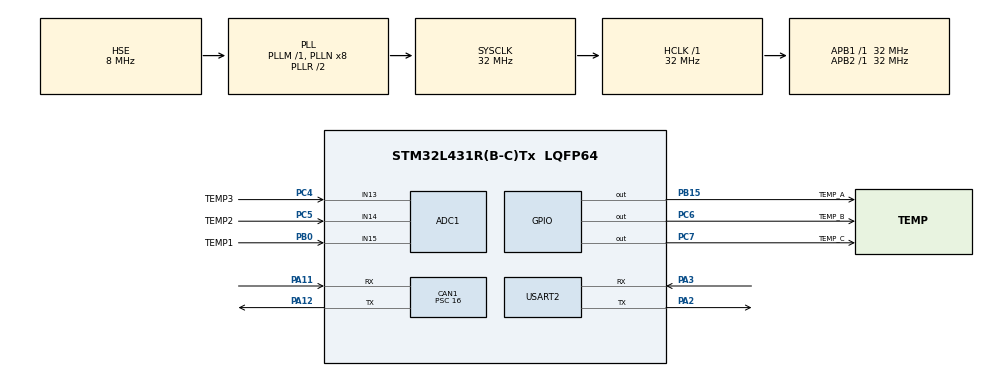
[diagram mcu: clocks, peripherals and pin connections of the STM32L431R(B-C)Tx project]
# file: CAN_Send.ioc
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ADC1.Channel-0\#ChannelRegularConversion=ADC_CHANNEL_15
ADC1.Channel-1\#ChannelRegularConversion=ADC_CHANNEL_14
ADC1.Channel-2\#ChannelRegularConversion=ADC_CHANNEL_13
ADC1.ContinuousConvMode=ENABLE
ADC1.DMAContinuousRequests=ENABLE
ADC1.NbrOfConversion=3
ADC1.NbrOfConversionFlag=1
ADC1.OffsetNumber-0\#ChannelRegularConversion=ADC_OFFSET_NONE
ADC1.OffsetNumber-1\#ChannelRegularConversion=ADC_OFFSET_NONE
ADC1.OffsetNumber-2\#ChannelRegularConversion=ADC_OFFSET_NONE
ADC1.Rank-0\#ChannelRegularConversion=1
ADC1.Rank-1\#ChannelRegularConversion=2
ADC1.Rank-2\#ChannelRegularConversion=3
ADC1.SamplingTime-0\#ChannelRegularConversion=ADC_SAMPLETIME_92CYCLES_5
ADC1.SamplingTime-1\#ChannelRegularConversion=ADC_SAMPLETIME_92CYCLES_5
ADC1.SamplingTime-2\#ChannelRegularConversion=ADC_SAMPLETIME_92CYCLES_5
ADC1.master=1
CAN1.ABOM=DISABLE
CAN1.AWUM=DISABLE
CAN1.BS1=CAN_BS1_5TQ
CAN1.BS2=CAN_BS2_2TQ
CAN1.CalculateBaudRate=250000
CAN1.CalculateTimeBit=4000
CAN1.CalculateTimeQuantum=500.0
CAN1.NART=DISABLE
CAN1.Prescaler=16
CAN1.RFLM=ENABLE
CAN1.TXFP=ENABLE
Dma.ADC1.0.Direction=DMA_PERIPH_TO_MEMORY
Dma.ADC1.0.Instance=DMA1_Channel1
Dma.ADC1.0.MemDataAlignment=DMA_MDATAALIGN_HALFWORD
Dma.ADC1.0.MemInc=DMA_MINC_ENABLE
Dma.ADC1.0.Mode=DMA_CIRCULAR
Dma.ADC1.0.PeriphDataAlignment=DMA_PDATAALIGN_HALFWORD
Dma.ADC1.0.PeriphInc=DMA_PINC_DISABLE
Dma.ADC1.0.Priority=DMA_PRIORITY_MEDIUM
Dma.Request0=ADC1
Mcu.Family=STM32L4
Mcu.Name=STM32L431R(B-C)Tx
Mcu.Package=LQFP64
NVIC.ADC1_IRQn=true\:0\:0\:false\:false\:true\:true\:true\:true
NVIC.CAN1_RX0_IRQn=true\:0\:0\:false\:false\:true\:true\:true\:true
NVIC.CAN1_RX1_IRQn=true\:0\:0\:false\:false\:true\:true\:true\:true
NVIC.CAN1_SCE_IRQn=true\:0\:0\:false\:false\:true\:true\:true\:true
NVIC.CAN1_TX_IRQn=true\:0\:0\:false\:false\:true\:true\:true\:true
NVIC.DMA1_Channel1_IRQn=true\:0\:0\:false\:false\:true\:false\:true\:true
NVIC.PriorityGroup=NVIC_PRIORITYGROUP_4
NVIC.USART2_IRQn=true\:0\:0\:false\:false\:true\:true\:true\:true
PA11.GPIO_Mode=GPIO_MODE_AF_PP
PA11.Mode=CAN_Activate
PA11.Signal=CAN1_RX
PA12.Mode=CAN_Activate
PA12.Signal=CAN1_TX
PA13\ (JTMS-SWDIO).Mode=Serial_Wire
PA13\ (JTMS-SWDIO).Signal=SYS_JTMS-SWDIO
PA14\ (JTCK-SWCLK).Mode=Serial_Wire
PA14\ (JTCK-SWCLK).Signal=SYS_JTCK-SWCLK
PA2.Mode=Asynchronous
PA2.Signal=USART2_TX
PA3.Mode=Asynchronous
PA3.Signal=USART2_RX
PB0.GPIO_Label=TEMP1
PB0.Signal=ADCx_IN15
PB15.GPIO_Label=TEMP_A
PB15.Signal=GPIO_Output
PC14-OSC32_IN\ (PC14).Mode=LSE-External-Oscillator
PC14-OSC32_IN\ (PC14).Signal=RCC_OSC32_IN
PC15-OSC32_OUT\ (PC15).Mode=LSE-External-Oscillator
PC15-OSC32_OUT\ (PC15).Signal=RCC_OSC32_OUT
PC4.GPIO_Label=TEMP3
PC4.Signal=ADCx_IN13
PC5.GPIO_Label=TEMP2
PC5.Signal=ADCx_IN14
PC6.GPIO_Label=TEMP_B
PC6.Signal=GPIO_Output
PC7.GPIO_Label=TEMP_C
PC7.Signal=GPIO_Output
PH0-OSC_IN\ (PH0).Mode=HSE-External-Oscillator
PH0-OSC_IN\ (PH0).Signal=RCC_OSC_IN
PH1-OSC_OUT\ (PH1).Mode=HSE-External-Oscillator
PH1-OSC_OUT\ (PH1).Signal=RCC_OSC_OUT
ProjectManager.HeapSize=0x200
ProjectManager.StackSize=0x400
ProjectManager.TargetToolchain=MDK-ARM V5.27
RCC.ADCFreq_Value=32000000
RCC.AHBFreq_Value=32000000
RCC.APB1Freq_Value=32000000
RCC.APB1TimFreq_Value=32000000
RCC.APB2Freq_Value=32000000
RCC.APB2TimFreq_Value=32000000
RCC.CortexFreq_Value=32000000
RCC.HCLKFreq_Value=32000000
RCC.HSE_VALUE=8000000
RCC.HSI48_VALUE=48000000
RCC.HSI_VALUE=16000000
RCC.MSI_VALUE=4000000
RCC.PLLSourceVirtual=RCC_PLLSOURCE_HSE
RCC.SYSCLKFreq_VALUE=32000000
RCC.SYSCLKSource=RCC_SYSCLKSOURCE_PLLCLK
RCC.VCOOutputFreq_Value=64000000
SH.ADCx_IN13.0=ADC1_IN13,IN13-Single-Ended
SH.ADCx_IN14.0=ADC1_IN14,IN14-Single-Ended
SH.ADCx_IN15.0=ADC1_IN15,IN15-Single-Ended
USART2.VirtualMode-Asynchronous=VM_ASYNC
board=custom

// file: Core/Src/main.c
/* USER CODE BEGIN Header */
/**
  ******************************************************************************
  * @file           : main.c
  * @brief          : Main program body
  ******************************************************************************
  * @attention
  *
  * Copyright (c) 2023 STMicroelectronics.
  * All rights reserved.
  *
  * This software is licensed under terms that can be found in the LICENSE file
  * in the root directory of this software component.
  * If no LICENSE file comes with this software, it is provided AS-IS.
  *
  ******************************************************************************
  */
/* USER CODE END Header */
#include "main.h"
#include "adc.h"
#include "can.h"
#include "dma.h"
#include "usart.h"
#include "gpio.h"

/* USER CODE BEGIN Includes */
uint8_t CAN1_Rx_data[8];
uint8_t CAN1_Tx_data[8];
uint16_t ADC_ConvertedValue[Temp_Sample_Num] = {0};

uint8_t rxbuff[256] = {0};
/* USER CODE END Includes */

void SystemClock_Config(void);

int main(void)
{

  /* MCU Configuration--------------------------------------------------------*/

  /* Reset of all peripherals, Initializes the Flash interface and the Systick. */
  HAL_Init();

  /* Configure the system clock */
  SystemClock_Config();

  /* Initialize all configured peripherals */
  MX_GPIO_Init();
  MX_DMA_Init();
  MX_CAN1_Init();
  MX_USART2_UART_Init();
  MX_ADC1_Init();
  /* USER CODE BEGIN 2 */
	Can_ConfigInit();

	printf("开始测试。\r\n");
  /* USER CODE END 2 */

  /* Infinite loop */
  while (1)
  {

    /* USER CODE BEGIN 3 */

//	CAN_Send();
	HAL_Delay(2000);

//	ADC_DMA_Temper_Sample();
	HAL_Delay(5000);

	HAL_Delay(4000);
			HAL_Delay(4000);
		HAL_Delay(4000);
		GetTemperature();
		HAL_Delay(1000);
//		Display_Temper();

//		ADC_Value_Test();

//
//	CAN_Send_ADCvalue();
//	HAL_Delay(5000);

//	ADC_Vol_Temper_Conver();
//	HAL_Delay(100);

//	CAN_ReceData();
//	HAL_CAN_RxFifo0MsgPendingCallback(&hcan1);
//		printf("receive = \r\n");
//	for(int i=0;i<8;i++)
//		{
//			printf("0x%x ,",CAN1_Rx_data[i]);
//		}
//
//		printf("\r\nRxMessage.StdId = 0x%x \n",RxMessage.StdId);
//		printf("RxMessage.ExtId = 0x%x \n",RxMessage.ExtId);
  }
  /* USER CODE END 3 */
}

void SystemClock_Config(void)
{
  RCC_OscInitTypeDef RCC_OscInitStruct = {0};
  RCC_ClkInitTypeDef RCC_ClkInitStruct = {0};

  /** Configure the main internal regulator output voltage
  */
  if (HAL_PWREx_ControlVoltageScaling(PWR_REGULATOR_VOLTAGE_SCALE1) != HAL_OK)
  {
    Error_Handler();
  }

  /** Initializes the RCC Oscillators according to the specified parameters
  * in the RCC_OscInitTypeDef structure.
  */
  RCC_OscInitStruct.OscillatorType = RCC_OSCILLATORTYPE_HSE;
  RCC_OscInitStruct.HSEState = RCC_HSE_ON;
  RCC_OscInitStruct.PLL.PLLState = RCC_PLL_ON;
  RCC_OscInitStruct.PLL.PLLSource = RCC_PLLSOURCE_HSE;
  RCC_OscInitStruct.PLL.PLLM = 1;
  RCC_OscInitStruct.PLL.PLLN = 8;
  RCC_OscInitStruct.PLL.PLLP = RCC_PLLP_DIV7;
  RCC_OscInitStruct.PLL.PLLQ = RCC_PLLQ_DIV2;
  RCC_OscInitStruct.PLL.PLLR = RCC_PLLR_DIV2;
  if (HAL_RCC_OscConfig(&RCC_OscInitStruct) != HAL_OK)
  {
    Error_Handler();
  }

  /** Initializes the CPU, AHB and APB buses clocks
  */
  RCC_ClkInitStruct.ClockType = RCC_CLOCKTYPE_HCLK|RCC_CLOCKTYPE_SYSCLK
                              |RCC_CLOCKTYPE_PCLK1|RCC_CLOCKTYPE_PCLK2;
  RCC_ClkInitStruct.SYSCLKSource = RCC_SYSCLKSOURCE_PLLCLK;
  RCC_ClkInitStruct.AHBCLKDivider = RCC_SYSCLK_DIV1;
  RCC_ClkInitStruct.APB1CLKDivider = RCC_HCLK_DIV1;
  RCC_ClkInitStruct.APB2CLKDivider = RCC_HCLK_DIV1;

  if (HAL_RCC_ClockConfig(&RCC_ClkInitStruct, FLASH_LATENCY_1) != HAL_OK)
  {
    Error_Handler();
  }
}

void Error_Handler(void)
{
  __disable_irq();
  while (1)
  {
  }
}
